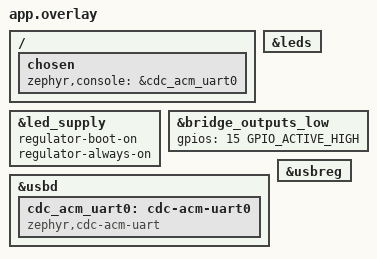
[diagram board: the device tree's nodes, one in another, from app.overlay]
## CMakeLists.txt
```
cmake_minimum_required(VERSION 3.20.0)
list(APPEND BOARD_ROOT "${CMAKE_CURRENT_SOURCE_DIR}/../..")
list(APPEND DTS_ROOT "${CMAKE_CURRENT_SOURCE_DIR}/../..")
find_package(Zephyr REQUIRED HINTS $ENV{ZEPHYR_BASE})
project(bridge_app_core)
target_sources(app PRIVATE src/main.c)
```

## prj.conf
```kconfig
# Board GPIO hogs establish safe levels; retain application-core GPIO ownership.
CONFIG_SOC_NRF53_CPUNET_ENABLE=y
CONFIG_GPIO=y
CONFIG_GPIO_HOGS=y
CONFIG_LED=y
CONFIG_LED_GPIO=y
CONFIG_REGULATOR=y
CONFIG_REGULATOR_FIXED=y

CONFIG_USB_DEVICE_STACK=y
CONFIG_USB_DEVICE_PRODUCT="SenseLab Bridge"
CONFIG_USB_DEVICE_INITIALIZE_AT_BOOT=n
CONFIG_SERIAL=y
CONFIG_CONSOLE=y
CONFIG_UART_CONSOLE=y
CONFIG_LOG=y
CONFIG_LOG_BACKEND_UART=y
CONFIG_BOOT_BANNER=n
```

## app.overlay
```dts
/ {
	chosen {
		zephyr,console = &cdc_acm_uart0;
	};
};

&leds { status = "okay"; };

&led_supply {
	status = "okay";
	/* This SDK's fixed driver lacks get_voltage; bounds make init fail.
	 * The hardware fixes VLED at 5 V; software only controls its enable.
	 */
	/delete-property/ regulator-min-microvolt;
	/delete-property/ regulator-max-microvolt;
	regulator-boot-on;
	regulator-always-on;
};

/* LED and supply drivers own P0.04/.05/.06/.14; keep MODE low. */
&bridge_outputs_low {
	gpios = <15 GPIO_ACTIVE_HIGH>;
};

zephyr_udc0: &usbd {
	status = "okay";
	cdc_acm_uart0: cdc-acm-uart0 {
		compatible = "zephyr,cdc-acm-uart";
	};
};

&usbreg { status = "okay"; };
```

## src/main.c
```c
#include <zephyr/kernel.h>
#include <zephyr/device.h>
#include <zephyr/drivers/led.h>
#include <zephyr/logging/log.h>
#include <zephyr/usb/usb_device.h>

LOG_MODULE_REGISTER(bridge_app, LOG_LEVEL_INF);

int main(void)
{
	const struct device *leds = DEVICE_DT_GET(DT_NODELABEL(leds));
	const struct device *supply = DEVICE_DT_GET(DT_NODELABEL(led_supply));
	int err = usb_enable(NULL);

	if (err) {
		LOG_ERR("USB initialization failed: %d", err);
	}

	if (!device_is_ready(leds) || !device_is_ready(supply)) {
		LOG_ERR("LEDs or 5 V supply not ready");
		return -ENODEV;
	}

	/* No DTR wait: blink even without an open USB terminal. */
	while (true) {
		for (uint32_t i = 0; i < DT_CHILD_NUM(DT_NODELABEL(leds)); i++) {
			err = led_on(leds, i);
			if (err) {
				LOG_ERR("LED %u on failed: %d", i, err);
				return err;
			}
			k_msleep(300);
			err = led_off(leds, i);
			if (err) {
				LOG_ERR("LED %u off failed: %d", i, err);
				return err;
			}
			k_msleep(100);
		}
	}
}
```
